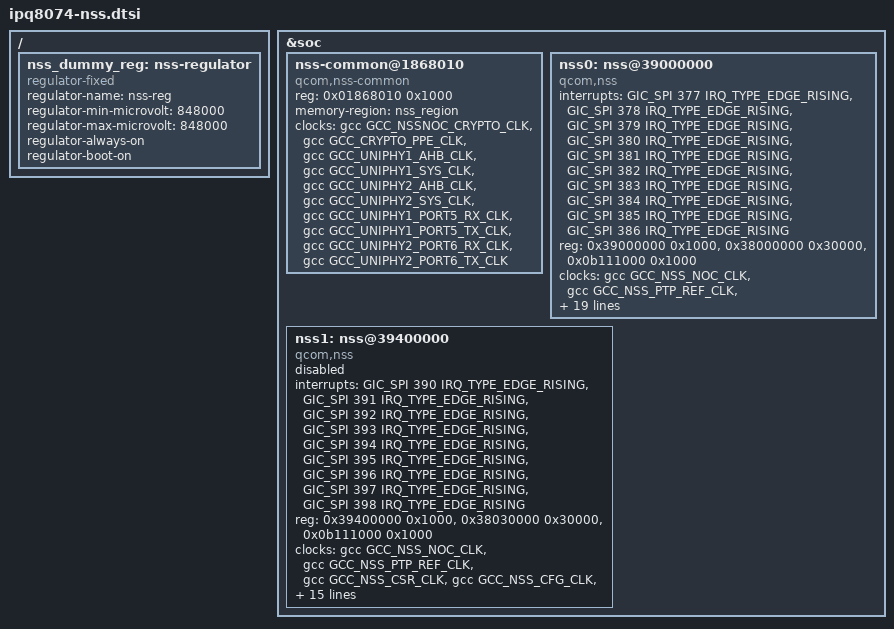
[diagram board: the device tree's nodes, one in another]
// SPDX-License-Identifier: GPL-2.0-only

/ {
	nss_dummy_reg: nss-regulator {
		compatible = "regulator-fixed";
		regulator-name = "nss-reg";
		regulator-min-microvolt = <848000>;
		regulator-max-microvolt = <848000>;
		regulator-always-on;
		regulator-boot-on;
	};
};

&soc {
	nss-common@1868010 {
		compatible = "qcom,nss-common";
		reg = <0x01868010 0x1000>;
		reg-names = "nss-misc-reset";
		memory-region = <&nss_region>;

		/*
		 * Blocks the firmware reaches while it runs that no other
		 * driver keeps clocked: an access through a gated clock stalls
		 * the bus with no error.
		 */
		clocks = <&gcc GCC_NSSNOC_CRYPTO_CLK>,
			 <&gcc GCC_CRYPTO_PPE_CLK>,
			 <&gcc GCC_UNIPHY1_AHB_CLK>,
			 <&gcc GCC_UNIPHY1_SYS_CLK>,
			 <&gcc GCC_UNIPHY2_AHB_CLK>,
			 <&gcc GCC_UNIPHY2_SYS_CLK>,
			 <&gcc GCC_UNIPHY1_PORT5_RX_CLK>,
			 <&gcc GCC_UNIPHY1_PORT5_TX_CLK>,
			 <&gcc GCC_UNIPHY2_PORT6_RX_CLK>,
			 <&gcc GCC_UNIPHY2_PORT6_TX_CLK>;
	};

	nss0: nss@39000000 {
		compatible = "qcom,nss";
		interrupts = <GIC_SPI 377 IRQ_TYPE_EDGE_RISING>,
			     <GIC_SPI 378 IRQ_TYPE_EDGE_RISING>,
			     <GIC_SPI 379 IRQ_TYPE_EDGE_RISING>,
			     <GIC_SPI 380 IRQ_TYPE_EDGE_RISING>,
			     <GIC_SPI 381 IRQ_TYPE_EDGE_RISING>,
			     <GIC_SPI 382 IRQ_TYPE_EDGE_RISING>,
			     <GIC_SPI 383 IRQ_TYPE_EDGE_RISING>,
			     <GIC_SPI 384 IRQ_TYPE_EDGE_RISING>,
			     <GIC_SPI 385 IRQ_TYPE_EDGE_RISING>,
			     <GIC_SPI 386 IRQ_TYPE_EDGE_RISING>;
		reg = <0x39000000 0x1000>,
		      <0x38000000 0x30000>,
		      <0x0b111000 0x1000>;
		reg-names = "nphys", "vphys", "qgic-phys";
		clocks = <&gcc GCC_NSS_NOC_CLK>,
			 <&gcc GCC_NSS_PTP_REF_CLK>,
			 <&gcc GCC_NSS_CSR_CLK>,
			 <&gcc GCC_NSS_CFG_CLK>,
			 <&gcc GCC_NSS_IMEM_CLK>,
			 <&gcc GCC_NSSNOC_QOSGEN_REF_CLK>,
			 <&gcc GCC_MEM_NOC_NSS_AXI_CLK>,
			 <&gcc GCC_NSSNOC_SNOC_CLK>,
			 <&gcc GCC_NSSNOC_TIMEOUT_REF_CLK>,
			 <&gcc GCC_NSS_CE_AXI_CLK>,
			 <&gcc GCC_NSS_CE_APB_CLK>,
			 <&gcc GCC_NSSNOC_CE_AXI_CLK>,
			 <&gcc GCC_NSSNOC_CE_APB_CLK>,
			 <&gcc GCC_NSSNOC_UBI0_AHB_CLK>,
			 <&gcc GCC_UBI0_CORE_CLK>,
			 <&gcc GCC_UBI0_AHB_CLK>,
			 <&gcc GCC_UBI0_AXI_CLK>,
			 <&gcc GCC_UBI0_MPT_CLK>,
			 <&gcc GCC_UBI0_NC_AXI_CLK>;
		clock-names = "nss-noc-clk",
			      "nss-ptp-ref-clk",
			      "nss-csr-clk",
			      "nss-cfg-clk",
			      "nss-imem-clk",
			      "nss-nssnoc-qosgen-ref-clk",
			      "nss-mem-noc-nss-axi-clk",
			      "nss-nssnoc-snoc-clk",
			      "nss-nssnoc-timeout-ref-clk",
			      "nss-ce-axi-clk",
			      "nss-ce-apb-clk",
			      "nss-nssnoc-ce-axi-clk",
			      "nss-nssnoc-ce-apb-clk",
			      "nss-nssnoc-ahb-clk",
			      "nss-core-clk",
			      "nss-ahb-clk",
			      "nss-axi-clk",
			      "nss-mpt-clk",
			      "nss-nc-axi-clk";
		qcom,id = <0>;
		qcom,load-addr = <0x40000000>;
		qcom,max-frequency = <1689600000>;
		mx-supply = <&nss_dummy_reg>;
		npu-supply = <&nss_dummy_reg>;
	};

	nss1: nss@39400000 {
		compatible = "qcom,nss";
		interrupts = <GIC_SPI 390 IRQ_TYPE_EDGE_RISING>,
			     <GIC_SPI 391 IRQ_TYPE_EDGE_RISING>,
			     <GIC_SPI 392 IRQ_TYPE_EDGE_RISING>,
			     <GIC_SPI 393 IRQ_TYPE_EDGE_RISING>,
			     <GIC_SPI 394 IRQ_TYPE_EDGE_RISING>,
			     <GIC_SPI 395 IRQ_TYPE_EDGE_RISING>,
			     <GIC_SPI 396 IRQ_TYPE_EDGE_RISING>,
			     <GIC_SPI 397 IRQ_TYPE_EDGE_RISING>,
			     <GIC_SPI 398 IRQ_TYPE_EDGE_RISING>;
		reg = <0x39400000 0x1000>,
		      <0x38030000 0x30000>,
		      <0x0b111000 0x1000>;
		reg-names = "nphys", "vphys", "qgic-phys";
		clocks = <&gcc GCC_NSS_NOC_CLK>,
			 <&gcc GCC_NSS_PTP_REF_CLK>,
			 <&gcc GCC_NSS_CSR_CLK>,
			 <&gcc GCC_NSS_CFG_CLK>,
			 <&gcc GCC_NSS_IMEM_CLK>,
			 <&gcc GCC_NSSNOC_QOSGEN_REF_CLK>,
			 <&gcc GCC_MEM_NOC_NSS_AXI_CLK>,
			 <&gcc GCC_NSSNOC_SNOC_CLK>,
			 <&gcc GCC_NSSNOC_TIMEOUT_REF_CLK>,
			 <&gcc GCC_NSS_CE_AXI_CLK>,
			 <&gcc GCC_NSS_CE_APB_CLK>,
			 <&gcc GCC_NSSNOC_CE_AXI_CLK>,
			 <&gcc GCC_NSSNOC_CE_APB_CLK>,
			 <&gcc GCC_NSSNOC_UBI1_AHB_CLK>,
			 <&gcc GCC_UBI1_CORE_CLK>,
			 <&gcc GCC_UBI1_AHB_CLK>,
			 <&gcc GCC_UBI1_AXI_CLK>,
			 <&gcc GCC_UBI1_MPT_CLK>,
			 <&gcc GCC_UBI1_NC_AXI_CLK>;
		clock-names = "nss-noc-clk",
			      "nss-ptp-ref-clk",
			      "nss-csr-clk",
			      "nss-cfg-clk",
			      "nss-imem-clk",
			      "nss-nssnoc-qosgen-ref-clk",
			      "nss-mem-noc-nss-axi-clk",
			      "nss-nssnoc-snoc-clk",
			      "nss-nssnoc-timeout-ref-clk",
			      "nss-ce-axi-clk",
			      "nss-ce-apb-clk",
			      "nss-nssnoc-ce-axi-clk",
			      "nss-nssnoc-ce-apb-clk",
			      "nss-nssnoc-ahb-clk",
			      "nss-core-clk",
			      "nss-ahb-clk",
			      "nss-axi-clk",
			      "nss-mpt-clk",
			      "nss-nc-axi-clk";
		qcom,id = <1>;
		qcom,load-addr = <0x40800000>;
		status = "disabled";
	};
};
